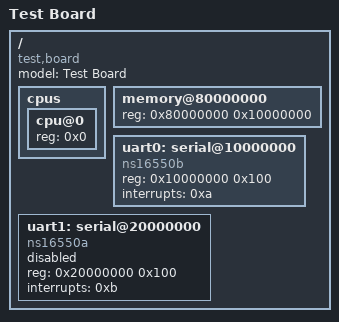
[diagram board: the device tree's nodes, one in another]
/dts-v1/;

/ {
	model = "Test Board";
	compatible = "test,board";

	cpus {
		#address-cells = <0x1>;
		#size-cells = <0x0>;

		cpu@0 {
			device_type = "cpu";
			reg = <0x0>;
			status = "okay";
		};
	};

	memory@80000000 {
		device_type = "memory";
		reg = <0x80000000 0x10000000>;
	};

	uart0: serial@10000000 {
		compatible = "ns16550a";
		reg = <0x10000000 0x100>;
		interrupts = <0xa>;
		status = "okay";
	};
};

&uart0 {
	compatible = "ns16550b";
};

/ {
	uart1: serial@20000000 {
		compatible = "ns16550a";
		reg = <0x20000000 0x100>;
		interrupts = <0xb>;
		status = "disabled";
	};
};
